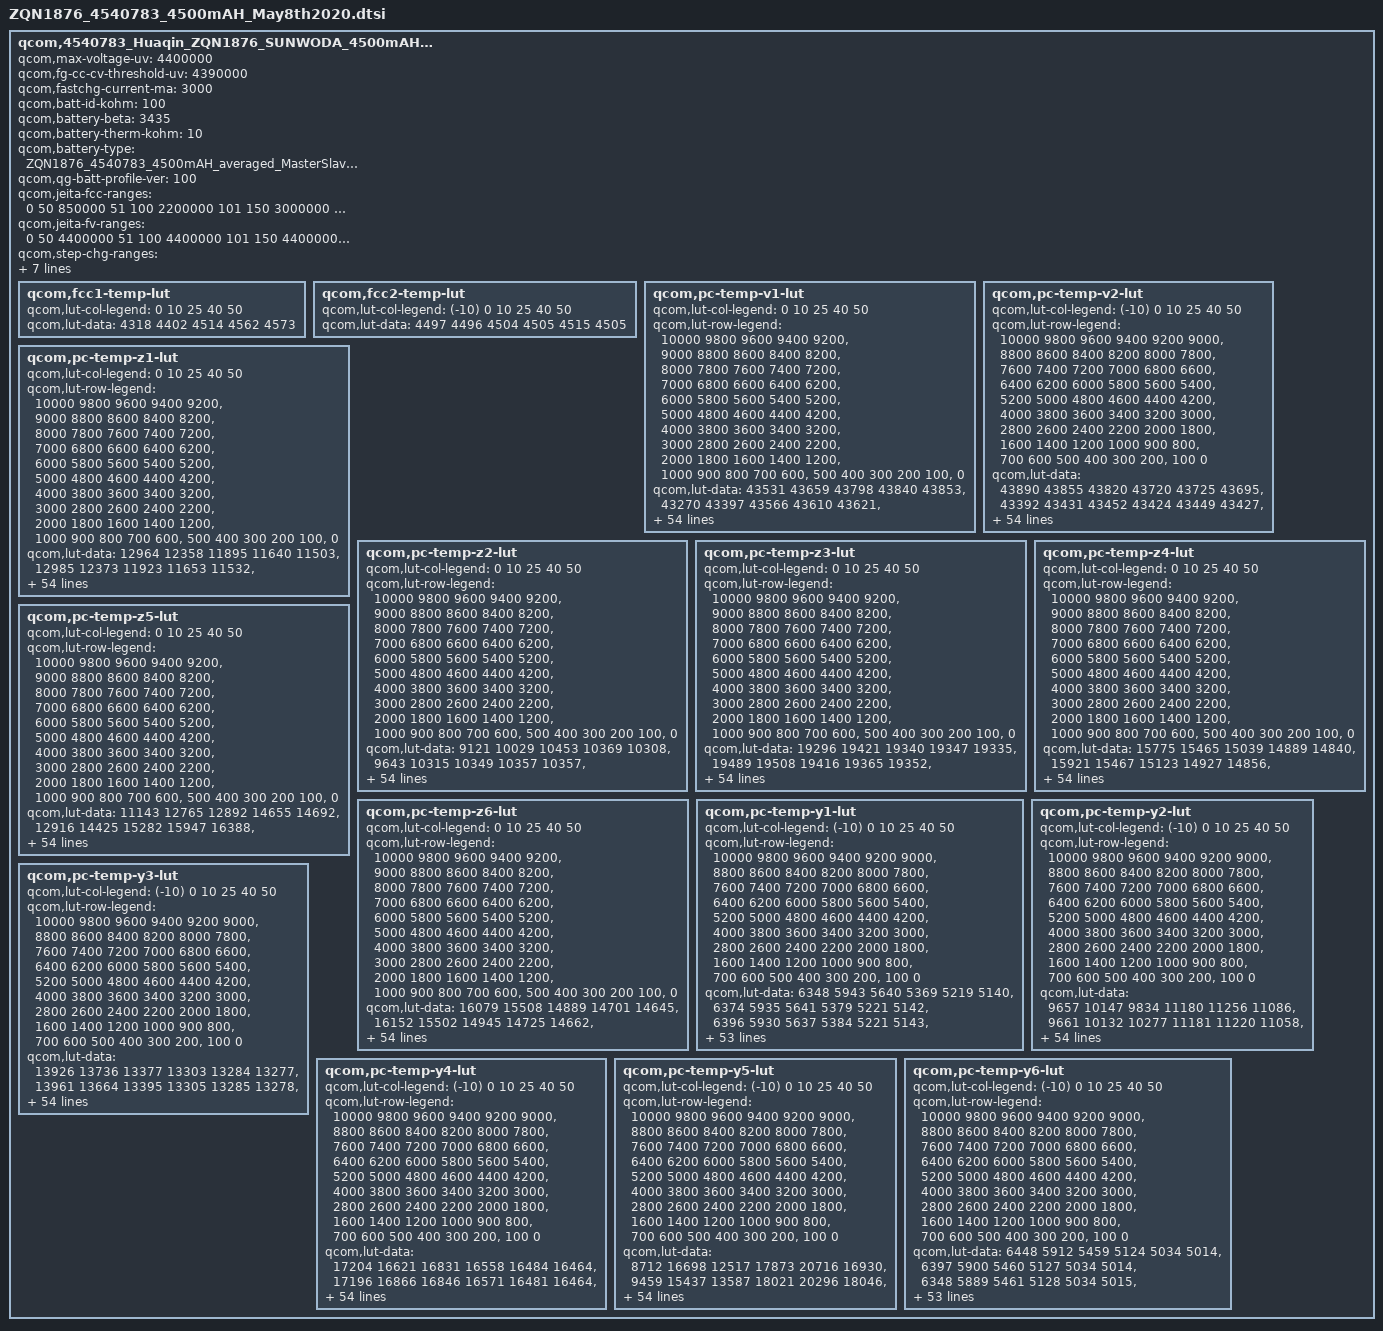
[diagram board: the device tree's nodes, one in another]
qcom,4540783_Huaqin_ZQN1876_SUNWODA_4500mAH_PM7250B {
    /* 4540783_Huaqin_ZQN1876_SUNWODA_4500mAH_PM7250B_averaged_MasterSlave_May8th2020 */
    qcom,max-voltage-uv = <4400000>;
    qcom,fg-cc-cv-threshold-uv = <4390000>;
    qcom,fastchg-current-ma = <3000>;
    qcom,batt-id-kohm = <100>;
    qcom,battery-beta = <3435>;
    qcom,battery-therm-kohm = <10>;
    qcom,battery-type = "ZQN1876_4540783_4500mAH_averaged_MasterSlave_May8th2020";
    qcom,qg-batt-profile-ver = <100>;

	qcom,jeita-fcc-ranges = <0  50  850000
				51 100  2200000
				101 150  3000000
				151 450  4400000
				451 600  2200000>;

	qcom,jeita-fv-ranges = <0   50  4400000
				51 100  4400000
				101 150  4400000
				151 450  4400000
				451 600  4100000>;

	qcom,step-chg-ranges = <3500000  4000000  4000000
				4000001  4200000  3500000
				4200001  4400000  2500000>;
	qcom,ocv-based-step-chg;

	/* COOL = 10 degc, WARM = 45 degC */
	qcom,jeita-soft-thresholds = <0x2AEE 0x0FB3>;
	/* COLD = 0 degC, HOT = 58 degC*/
	qcom,jeita-hard-thresholds = <0x3733 0x0ACB>;
	/* COOL hys = 13 degC, WARM hys = 42 degC */
	qcom,jeita-soft-hys-thresholds = <0x279A 0x1124>;
	qcom,jeita-soft-fcc-ua = <880000 2200000>;
	qcom,jeita-soft-fv-uv = <4400000 4100000>;
	qcom,fcc1-temp-lut {
		qcom,lut-col-legend = <0 10 25 40 50>;
		qcom,lut-data = <4318 4402 4514 4562 4573>;
	};

	qcom,fcc2-temp-lut {
		qcom,lut-col-legend = <(-10) 0 10 25 40 50>;
		qcom,lut-data = <4497 4496 4504 4505 4515 4505>;
	};

	qcom,pc-temp-v1-lut {
		qcom,lut-col-legend = <0 10 25 40 50>;
		qcom,lut-row-legend = <10000 9800 9600 9400 9200>,
			<9000 8800 8600 8400 8200>,
			<8000 7800 7600 7400 7200>,
			<7000 6800 6600 6400 6200>,
			<6000 5800 5600 5400 5200>,
			<5000 4800 4600 4400 4200>,
			<4000 3800 3600 3400 3200>,
			<3000 2800 2600 2400 2200>,
			<2000 1800 1600 1400 1200>,
			<1000 900 800 700 600>,
			<500 400 300 200 100>,
			<0>;
		qcom,lut-data = <43531 43659 43798 43840 43853>,
			<43270 43397 43566 43610 43621>,
			<43013 43146 43315 43373 43390>,
			<42767 42905 43068 43135 43159>,
			<42538 42671 42826 42899 42926>,
			<42320 42442 42586 42662 42689>,
			<42109 42218 42352 42428 42455>,
			<41906 42002 42121 42194 42223>,
			<41710 41793 41897 41963 41992>,
			<41524 41590 41677 41734 41762>,
			<41350 41404 41465 41507 41534>,
			<41160 41226 41271 41289 41311>,
			<40940 41027 41086 41077 41091>,
			<40699 40792 40873 40869 40879>,
			<40448 40548 40612 40649 40674>,
			<40165 40302 40360 40431 40477>,
			<39928 40053 40157 40238 40287>,
			<39791 39873 39980 40064 40105>,
			<39691 39769 39829 39900 39930>,
			<39587 39675 39713 39749 39770>,
			<39483 39528 39584 39598 39611>,
			<39371 39329 39376 39408 39421>,
			<39223 39133 39123 39172 39186>,
			<39032 38935 38938 38968 38976>,
			<38867 38758 38805 38814 38820>,
			<38747 38664 38695 38683 38688>,
			<38647 38608 38600 38570 38572>,
			<38572 38558 38519 38471 38471>,
			<38513 38502 38441 38382 38379>,
			<38466 38448 38367 38301 38293>,
			<38424 38398 38301 38229 38216>,
			<38389 38350 38247 38165 38147>,
			<38357 38306 38198 38109 38085>,
			<38329 38267 38155 38057 38027>,
			<38303 38232 38117 38012 37974>,
			<38274 38198 38078 37967 37923>,
			<38247 38169 38041 37920 37868>,
			<38210 38134 38001 37871 37811>,
			<38143 38073 37944 37808 37740>,
			<38048 37977 37857 37721 37648>,
			<37954 37869 37753 37618 37542>,
			<37858 37744 37633 37500 37424>,
			<37731 37600 37493 37363 37290>,
			<37549 37426 37330 37201 37126>,
			<37390 37288 37184 37067 36996>,
			<37284 37224 37087 36985 36920>,
			<37249 37187 37058 36958 36897>,
			<37217 37160 37042 36943 36880>,
			<37187 37136 37024 36924 36861>,
			<37127 37078 36975 36855 36785>,
			<36898 36826 36715 36566 36488>,
			<36443 36373 36276 36115 36043>,
			<35861 35786 35703 35527 35463>,
			<35073 34987 34915 34722 34669>,
			<33819 33729 33689 33451 33434>,
			<30000 30000 30000 30000 30000>;
	};

	qcom,pc-temp-v2-lut {
		qcom,lut-col-legend = <(-10) 0 10 25 40 50>;
		qcom,lut-row-legend = <10000 9800 9600 9400 9200 9000>,
			<8800 8600 8400 8200 8000 7800>,
			<7600 7400 7200 7000 6800 6600>,
			<6400 6200 6000 5800 5600 5400>,
			<5200 5000 4800 4600 4400 4200>,
			<4000 3800 3600 3400 3200 3000>,
			<2800 2600 2400 2200 2000 1800>,
			<1600 1400 1200 1000 900 800>,
			<700 600 500 400 300 200>,
			<100 0>;
		qcom,lut-data = <43890 43855 43820 43720 43725 43695>,
			<43392 43431 43452 43424 43449 43427>,
			<42957 43050 43119 43146 43184 43168>,
			<42599 42719 42827 42885 42930 42920>,
			<42300 42428 42571 42642 42688 42682>,
			<42023 42167 42326 42405 42450 42446>,
			<41694 41931 42082 42171 42214 42212>,
			<41416 41716 41841 41941 41981 41980>,
			<41371 41508 41576 41716 41752 41751>,
			<41376 41302 41271 41494 41529 41525>,
			<41379 41129 41066 41280 41307 41303>,
			<41200 41018 41000 41080 41088 41085>,
			<40820 40915 40951 40884 40872 40871>,
			<40433 40685 40776 40668 40664 40664>,
			<39972 40165 40278 40429 40463 40462>,
			<39603 39752 39890 40201 40268 40268>,
			<39402 39605 39765 39994 40079 40085>,
			<39243 39498 39675 39805 39898 39909>,
			<39049 39344 39540 39646 39730 39740>,
			<38815 39139 39355 39514 39579 39583>,
			<38626 38919 39158 39365 39410 39411>,
			<38506 38669 38949 39150 39187 39191>,
			<38413 38428 38735 38913 38954 38959>,
			<38335 38299 38542 38731 38770 38776>,
			<38270 38224 38357 38580 38615 38622>,
			<38212 38167 38216 38451 38483 38490>,
			<38157 38116 38122 38340 38370 38376>,
			<38105 38072 38051 38241 38271 38276>,
			<38053 38030 37995 38152 38181 38184>,
			<38002 37990 37951 38070 38099 38099>,
			<37952 37951 37913 37995 38026 38023>,
			<37903 37913 37881 37920 37960 37956>,
			<37854 37875 37850 37853 37899 37894>,
			<37801 37835 37817 37803 37833 37827>,
			<37745 37794 37781 37766 37763 37756>,
			<37687 37749 37741 37725 37689 37676>,
			<37627 37703 37696 37677 37609 37578>,
			<37565 37651 37643 37620 37527 37471>,
			<37493 37588 37578 37551 37448 37382>,
			<37411 37511 37497 37467 37370 37305>,
			<37324 37422 37401 37372 37287 37223>,
			<37231 37310 37281 37262 37191 37131>,
			<37141 37184 37151 37140 37080 37025>,
			<37064 37049 37024 36997 36935 36882>,
			<36991 36931 36912 36894 36830 36782>,
			<36915 36850 36818 36842 36795 36744>,
			<36868 36820 36778 36825 36782 36733>,
			<36814 36790 36734 36801 36765 36717>,
			<36744 36743 36679 36756 36727 36682>,
			<36618 36654 36584 36629 36608 36563>,
			<36371 36428 36371 36289 36262 36205>,
			<35964 35991 35923 35757 35741 35695>,
			<35379 35372 35283 35058 35070 35038>,
			<34530 34498 34390 34074 34142 34128>,
			<33145 33074 32953 32506 32726 32724>,
			<29068 28775 28334 28927 27750 28531>;
	};

	qcom,pc-temp-z1-lut {
		qcom,lut-col-legend = <0 10 25 40 50>;
		qcom,lut-row-legend = <10000 9800 9600 9400 9200>,
			<9000 8800 8600 8400 8200>,
			<8000 7800 7600 7400 7200>,
			<7000 6800 6600 6400 6200>,
			<6000 5800 5600 5400 5200>,
			<5000 4800 4600 4400 4200>,
			<4000 3800 3600 3400 3200>,
			<3000 2800 2600 2400 2200>,
			<2000 1800 1600 1400 1200>,
			<1000 900 800 700 600>,
			<500 400 300 200 100>,
			<0>;
		qcom,lut-data = <12964 12358 11895 11640 11503>,
			<12985 12373 11923 11653 11532>,
			<12984 12373 11922 11649 11529>,
			<12983 12367 11921 11646 11527>,
			<12980 12362 11913 11639 11523>,
			<12971 12356 11903 11629 11516>,
			<12961 12349 11894 11620 11510>,
			<12944 12344 11884 11612 11505>,
			<12929 12337 11877 11605 11502>,
			<12926 12332 11870 11602 11499>,
			<12927 12333 11866 11599 11497>,
			<12924 12336 11867 11598 11495>,
			<12895 12333 11869 11598 11494>,
			<12855 12302 11869 11598 11493>,
			<12836 12272 11855 11591 11492>,
			<12820 12270 11840 11579 11491>,
			<12809 12273 11837 11578 11491>,
			<12801 12275 11838 11580 11492>,
			<12789 12277 11840 11584 11493>,
			<12784 12281 11846 11588 11493>,
			<12777 12287 11852 11591 11494>,
			<12770 12300 11854 11593 11495>,
			<12778 12306 11855 11594 11496>,
			<12797 12304 11858 11596 11497>,
			<12808 12301 11868 11599 11500>,
			<12802 12302 11875 11602 11504>,
			<12792 12306 11873 11606 11508>,
			<12796 12308 11870 11610 11511>,
			<12817 12313 11870 11614 11515>,
			<12836 12322 11882 11618 11519>,
			<12840 12325 11892 11622 11523>,
			<12840 12324 11896 11625 11526>,
			<12840 12325 11898 11630 11530>,
			<12843 12330 11899 11633 11533>,
			<12845 12338 11898 11637 11538>,
			<12849 12344 11897 11641 11542>,
			<12866 12347 11897 11644 11546>,
			<12880 12347 11898 11647 11550>,
			<12888 12348 11902 11652 11554>,
			<12896 12350 11913 11661 11557>,
			<12897 12354 11923 11668 11561>,
			<12883 12376 11930 11671 11564>,
			<12885 12387 11937 11673 11568>,
			<12919 12369 11949 11678 11572>,
			<12941 12389 11953 11685 11576>,
			<12914 12380 11960 11688 11578>,
			<12917 12385 11947 11688 11579>,
			<12921 12377 11945 11690 11579>,
			<12903 12382 11954 11693 11583>,
			<12942 12400 11950 11698 11589>,
			<12928 12394 11962 11707 11596>,
			<12952 12423 11972 11722 11603>,
			<12962 12429 11990 11725 11611>,
			<12982 12474 12001 11742 11623>,
			<12982 12474 12001 11742 11623>,
			<12982 12474 12001 11742 11623>;
	};

	qcom,pc-temp-z2-lut {
		qcom,lut-col-legend = <0 10 25 40 50>;
		qcom,lut-row-legend = <10000 9800 9600 9400 9200>,
			<9000 8800 8600 8400 8200>,
			<8000 7800 7600 7400 7200>,
			<7000 6800 6600 6400 6200>,
			<6000 5800 5600 5400 5200>,
			<5000 4800 4600 4400 4200>,
			<4000 3800 3600 3400 3200>,
			<3000 2800 2600 2400 2200>,
			<2000 1800 1600 1400 1200>,
			<1000 900 800 700 600>,
			<500 400 300 200 100>,
			<0>;
		qcom,lut-data = <9121 10029 10453 10369 10308>,
			<9643 10315 10349 10357 10357>,
			<9954 10380 10513 10430 10343>,
			<10181 10389 10569 10499 10331>,
			<10181 10392 10548 10486 10323>,
			<10168 10379 10519 10445 10301>,
			<10156 10352 10496 10413 10274>,
			<10143 10333 10473 10383 10236>,
			<10132 10318 10455 10364 10206>,
			<10124 10309 10438 10362 10209>,
			<10119 10307 10429 10360 10223>,
			<10112 10306 10433 10363 10238>,
			<10099 10306 10446 10380 10258>,
			<10086 10321 10464 10400 10271>,
			<10084 10338 10500 10429 10259>,
			<10094 10348 10525 10462 10239>,
			<10108 10355 10499 10454 10237>,
			<10124 10363 10443 10377 10256>,
			<10144 10371 10429 10329 10281>,
			<10165 10381 10459 10337 10300>,
			<10187 10400 10502 10358 10323>,
			<10208 10430 10562 10417 10390>,
			<10224 10446 10630 10579 10580>,
			<10238 10446 10644 10669 10707>,
			<10251 10445 10617 10633 10708>,
			<10262 10446 10595 10581 10679>,
			<10271 10450 10615 10589 10627>,
			<10283 10456 10655 10642 10513>,
			<10298 10462 10663 10663 10424>,
			<10312 10470 10651 10569 10363>,
			<10323 10479 10634 10460 10312>,
			<10331 10491 10613 10442 10278>,
			<10341 10500 10592 10435 10250>,
			<10352 10503 10589 10435 10242>,
			<10363 10506 10609 10458 10265>,
			<10375 10509 10630 10492 10304>,
			<10388 10523 10643 10533 10357>,
			<10402 10541 10657 10591 10428>,
			<10425 10560 10672 10624 10474>,
			<10449 10583 10692 10647 10500>,
			<10397 10593 10705 10662 10519>,
			<10026 10594 10708 10668 10526>,
			<9908 10597 10709 10673 10523>,
			<10060 10622 10701 10671 10546>,
			<10054 10617 10716 10621 10541>,
			<10069 14375 10759 10549 10465>,
			<10196 13650 10724 10540 10464>,
			<10173 16147 10685 10568 10497>,
			<10128 21114 10688 10588 10542>,
			<10067 20543 10765 10677 10569>,
			<9888 19923 10753 10536 10401>,
			<9848 18828 10666 10450 10302>,
			<9718 18085 10651 10403 10271>,
			<9643 14449 10584 10365 10218>,
			<9643 14449 10584 10365 10218>,
			<9643 14449 10584 10365 10218>;
	};

	qcom,pc-temp-z3-lut {
		qcom,lut-col-legend = <0 10 25 40 50>;
		qcom,lut-row-legend = <10000 9800 9600 9400 9200>,
			<9000 8800 8600 8400 8200>,
			<8000 7800 7600 7400 7200>,
			<7000 6800 6600 6400 6200>,
			<6000 5800 5600 5400 5200>,
			<5000 4800 4600 4400 4200>,
			<4000 3800 3600 3400 3200>,
			<3000 2800 2600 2400 2200>,
			<2000 1800 1600 1400 1200>,
			<1000 900 800 700 600>,
			<500 400 300 200 100>,
			<0>;
		qcom,lut-data = <19296 19421 19340 19347 19335>,
			<19489 19508 19416 19365 19352>,
			<19629 19549 19445 19385 19363>,
			<19725 19572 19457 19396 19374>,
			<19737 19582 19463 19399 19379>,
			<19742 19585 19466 19401 19384>,
			<19744 19586 19466 19401 19385>,
			<19740 19586 19466 19402 19385>,
			<19734 19586 19465 19402 19384>,
			<19727 19585 19462 19400 19383>,
			<19718 19581 19459 19396 19381>,
			<19713 19572 19453 19394 19379>,
			<19716 19566 19445 19393 19377>,
			<19721 19560 19443 19392 19375>,
			<19728 19556 19446 19390 19371>,
			<19739 19554 19448 19389 19366>,
			<19747 19553 19445 19386 19362>,
			<19735 19550 19436 19380 19359>,
			<19704 19536 19429 19373 19356>,
			<19681 19522 19420 19366 19352>,
			<19666 19524 19415 19361 19349>,
			<19657 19535 19418 19361 19349>,
			<19661 19541 19424 19369 19357>,
			<19680 19540 19425 19373 19364>,
			<19691 19537 19417 19370 19366>,
			<19688 19534 19410 19367 19368>,
			<19681 19528 19415 19373 19373>,
			<19675 19525 19428 19397 19386>,
			<19671 19526 19437 19408 19393>,
			<19666 19528 19446 19406 19390>,
			<19660 19529 19451 19403 19384>,
			<19654 19529 19449 19399 19379>,
			<19647 19530 19443 19392 19373>,
			<19640 19528 19437 19386 19366>,
			<19633 19525 19432 19379 19360>,
			<19626 19521 19428 19374 19355>,
			<19619 19517 19424 19371 19352>,
			<19612 19513 19421 19368 19349>,
			<19608 19508 19418 19367 19348>,
			<19603 19503 19415 19366 19350>,
			<19562 19499 19412 19365 19352>,
			<19345 19494 19409 19365 19352>,
			<19263 19489 19407 19365 19353>,
			<19262 19483 19402 19365 19356>,
			<19262 19401 19390 19359 19354>,
			<19262 19258 19385 19345 19342>,
			<19261 19257 19383 19345 19333>,
			<19261 19257 19378 19338 19330>,
			<19261 19256 19375 19334 19323>,
			<19262 19256 19361 19332 19326>,
			<19263 19256 19374 19347 19343>,
			<19263 19256 19380 19354 19345>,
			<19265 19256 19359 19353 19346>,
			<19266 19257 19357 19351 19346>,
			<19266 19257 19357 19351 19346>,
			<19266 19257 19357 19351 19346>;
	};

	qcom,pc-temp-z4-lut {
		qcom,lut-col-legend = <0 10 25 40 50>;
		qcom,lut-row-legend = <10000 9800 9600 9400 9200>,
			<9000 8800 8600 8400 8200>,
			<8000 7800 7600 7400 7200>,
			<7000 6800 6600 6400 6200>,
			<6000 5800 5600 5400 5200>,
			<5000 4800 4600 4400 4200>,
			<4000 3800 3600 3400 3200>,
			<3000 2800 2600 2400 2200>,
			<2000 1800 1600 1400 1200>,
			<1000 900 800 700 600>,
			<500 400 300 200 100>,
			<0>;
		qcom,lut-data = <15775 15465 15039 14889 14840>,
			<15921 15467 15123 14927 14856>,
			<15754 15440 15081 14903 14843>,
			<15557 15289 15032 14869 14823>,
			<15417 15137 14968 14841 14804>,
			<15290 15050 14905 14812 14784>,
			<15188 14979 14863 14788 14766>,
			<15106 14923 14828 14767 14747>,
			<15039 14877 14800 14749 14732>,
			<14988 14841 14775 14734 14721>,
			<14947 14814 14756 14722 14713>,
			<14912 14792 14745 14717 14706>,
			<14875 14774 14736 14714 14702>,
			<14847 14755 14734 14712 14698>,
			<14843 14744 14737 14709 14694>,
			<14857 14751 14740 14706 14691>,
			<14869 14773 14735 14700 14687>,
			<14856 14781 14723 14689 14681>,
			<14820 14752 14712 14681 14676>,
			<14792 14719 14697 14680 14673>,
			<14771 14721 14689 14679 14670>,
			<14757 14747 14721 14690 14679>,
			<14762 14778 14790 14740 14727>,
			<14790 14827 14824 14776 14759>,
			<14812 14874 14840 14790 14761>,
			<14828 14878 14847 14797 14762>,
			<14842 14857 14834 14787 14756>,
			<14845 14835 14807 14748 14727>,
			<14835 14818 14786 14724 14706>,
			<14822 14802 14769 14715 14699>,
			<14811 14789 14757 14710 14695>,
			<14798 14778 14752 14707 14691>,
			<14786 14769 14749 14704 14688>,
			<14776 14763 14747 14703 14687>,
			<14766 14759 14745 14704 14687>,
			<14756 14755 14744 14704 14688>,
			<14746 14747 14742 14704 14689>,
			<14739 14742 14741 14705 14691>,
			<14734 14742 14741 14705 14693>,
			<14732 14742 14740 14708 14696>,
			<14763 14742 14740 14709 14697>,
			<14972 14732 14731 14703 14692>,
			<15049 14721 14718 14692 14685>,
			<15030 14711 14711 14690 14684>,
			<14950 14748 14692 14681 14677>,
			<14928 14859 14668 14666 14657>,
			<14920 14854 14662 14658 14655>,
			<14915 14848 14653 14647 14642>,
			<14908 14838 14644 14635 14629>,
			<14904 14835 14650 14635 14625>,
			<14909 14845 14656 14647 14643>,
			<14923 14852 14656 14645 14648>,
			<14930 14856 14677 14648 14651>,
			<14941 14858 14681 14652 14651>,
			<14941 14858 14681 14652 14651>,
			<14941 14858 14681 14652 14651>;
	};

	qcom,pc-temp-z5-lut {
		qcom,lut-col-legend = <0 10 25 40 50>;
		qcom,lut-row-legend = <10000 9800 9600 9400 9200>,
			<9000 8800 8600 8400 8200>,
			<8000 7800 7600 7400 7200>,
			<7000 6800 6600 6400 6200>,
			<6000 5800 5600 5400 5200>,
			<5000 4800 4600 4400 4200>,
			<4000 3800 3600 3400 3200>,
			<3000 2800 2600 2400 2200>,
			<2000 1800 1600 1400 1200>,
			<1000 900 800 700 600>,
			<500 400 300 200 100>,
			<0>;
		qcom,lut-data = <11143 12765 12892 14655 14692>,
			<12916 14425 15282 15947 16388>,
			<14412 15765 16546 17451 17462>,
			<15629 16889 17613 18504 18585>,
			<16354 17932 18509 18946 19382>,
			<16905 18919 19334 19219 20052>,
			<17452 19902 20211 19590 20671>,
			<18016 21090 21103 20175 21217>,
			<18549 22605 22075 20863 21787>,
			<19033 24066 23321 21650 22543>,
			<19517 25179 24262 22506 23422>,
			<20103 26208 24661 23144 24203>,
			<20883 27555 25076 23569 25056>,
			<21951 30404 26009 24132 25575>,
			<23732 32698 29518 25855 25470>,
			<27445 31915 32240 28009 25242>,
			<30098 29433 30610 28124 25260>,
			<29056 28377 27103 26436 25964>,
			<26502 28444 26513 25359 26762>,
			<25529 28603 30402 25880 27420>,
			<26033 32891 34254 26739 28057>,
			<27141 47305 35579 27233 28340>,
			<32432 54920 36428 27669 28580>,
			<47567 50806 35734 27617 28626>,
			<56265 43942 28779 23993 25438>,
			<54139 38978 23217 19604 20853>,
			<50220 34319 23484 20029 20702>,
			<47656 32029 24484 23539 23369>,
			<45862 32333 26159 26554 25721>,
			<44462 33113 30277 28503 27107>,
			<43469 34311 34128 30147 28241>,
			<42647 36953 36021 31614 29164>,
			<41866 39681 37414 32924 30000>,
			<41042 41687 38563 33545 30433>,
			<40295 43440 39682 33834 30648>,
			<39699 44230 40249 33985 30753>,
			<39186 44669 39944 33797 30536>,
			<39193 44926 39124 33168 29911>,
			<40539 44472 37864 32297 29264>,
			<42332 42954 35301 30213 28553>,
			<39619 41255 33082 28541 27945>,
			<19170 38971 32103 28374 27730>,
			<11492 37148 31236 28390 27896>,
			<11538 36192 29000 28352 30099>,
			<11749 28248 28974 27085 30111>,
			<11757 11875 31812 23821 25646>,
			<11693 11841 32831 24924 22064>,
			<11687 11808 31293 24228 23457>,
			<11681 11708 31832 26644 26009>,
			<11705 11736 24542 24946 28988>,
			<11733 11757 25148 24235 27268>,
			<11645 11651 24945 25322 24472>,
			<11578 11566 18078 23168 22382>,
			<11467 11473 17078 20573 20096>,
			<11467 11473 17078 20573 20096>,
			<11467 11473 17078 20573 20096>;
	};

	qcom,pc-temp-z6-lut {
		qcom,lut-col-legend = <0 10 25 40 50>;
		qcom,lut-row-legend = <10000 9800 9600 9400 9200>,
			<9000 8800 8600 8400 8200>,
			<8000 7800 7600 7400 7200>,
			<7000 6800 6600 6400 6200>,
			<6000 5800 5600 5400 5200>,
			<5000 4800 4600 4400 4200>,
			<4000 3800 3600 3400 3200>,
			<3000 2800 2600 2400 2200>,
			<2000 1800 1600 1400 1200>,
			<1000 900 800 700 600>,
			<500 400 300 200 100>,
			<0>;
		qcom,lut-data = <16079 15508 14889 14701 14645>,
			<16152 15502 14945 14725 14662>,
			<16063 15473 14934 14721 14661>,
			<15951 15382 14918 14714 14658>,
			<15851 15288 14887 14704 14653>,
			<15747 15226 14852 14689 14646>,
			<15661 15171 14827 14677 14638>,
			<15591 15128 14806 14667 14630>,
			<15532 15093 14787 14658 14622>,
			<15484 15062 14771 14649 14616>,
			<15443 15036 14758 14641 14611>,
			<15407 15012 14748 14637 14606>,
			<15367 14990 14740 14635 14603>,
			<15333 14964 14736 14634 14600>,
			<15320 14947 14735 14630 14596>,
			<15316 14948 14733 14626 14591>,
			<15311 14953 14728 14620 14587>,
			<15290 14955 14719 14613 14583>,
			<15252 14938 14711 14606 14579>,
			<15228 14919 14702 14602 14576>,
			<15215 14922 14697 14599 14572>,
			<15208 14941 14714 14605 14576>,
			<15214 14962 14749 14631 14601>,
			<15238 14984 14763 14649 14619>,
			<15256 15004 14767 14654 14623>,
			<15261 15005 14769 14657 14626>,
			<15265 14995 14767 14656 14625>,
			<15265 14985 14763 14653 14621>,
			<15261 14981 14761 14649 14616>,
			<15256 14977 14760 14646 14612>,
			<15250 14974 14759 14643 14608>,
			<15242 14970 14756 14639 14604>,
			<15235 14967 14753 14636 14600>,
			<15231 14966 14751 14633 14597>,
			<15227 14965 14749 14630 14594>,
			<15223 14964 14747 14628 14591>,
			<15219 14963 14747 14627 14591>,
			<15217 14962 14746 14626 14591>,
			<15220 14963 14746 14626 14591>,
			<15224 14966 14747 14628 14593>,
			<15224 14967 14748 14629 14596>,
			<15217 14966 14745 14627 14594>,
			<15215 14966 14742 14624 14592>,
			<15218 14967 14739 14624 14594>,
			<15204 14953 14730 14619 14590>,
			<15197 14936 14720 14605 14576>,
			<15194 14936 14718 14602 14571>,
			<15194 14933 14712 14594 14564>,
			<15194 14929 14708 14587 14554>,
			<15198 14932 14707 14587 14555>,
			<15211 14946 14720 14603 14573>,
			<15222 14956 14727 14608 14579>,
			<15239 14966 14731 14612 14583>,
			<15267 14981 14738 14616 14586>,
			<15267 14981 14738 14616 14586>,
			<15267 14981 14738 14616 14586>;
	};

	qcom,pc-temp-y1-lut {
		qcom,lut-col-legend = <(-10) 0 10 25 40 50>;
		qcom,lut-row-legend = <10000 9800 9600 9400 9200 9000>,
			<8800 8600 8400 8200 8000 7800>,
			<7600 7400 7200 7000 6800 6600>,
			<6400 6200 6000 5800 5600 5400>,
			<5200 5000 4800 4600 4400 4200>,
			<4000 3800 3600 3400 3200 3000>,
			<2800 2600 2400 2200 2000 1800>,
			<1600 1400 1200 1000 900 800>,
			<700 600 500 400 300 200>,
			<100 0>;
		qcom,lut-data = <6348 5943 5640 5369 5219 5140>,
			<6374 5935 5641 5379 5221 5142>,
			<6396 5930 5637 5384 5221 5143>,
			<6414 5927 5630 5387 5220 5144>,
			<6425 5926 5624 5387 5219 5144>,
			<6429 5927 5622 5385 5216 5144>,
			<6424 5933 5620 5380 5212 5142>,
			<6415 5943 5618 5372 5206 5138>,
			<6415 5945 5619 5369 5203 5135>,
			<6425 5943 5622 5367 5202 5132>,
			<6431 5941 5625 5365 5200 5130>,
			<6424 5944 5631 5364 5197 5129>,
			<6414 5948 5637 5363 5195 5128>,
			<6414 5948 5636 5362 5192 5126>,
			<6429 5942 5626 5361 5189 5125>,
			<6441 5938 5621 5360 5188 5125>,
			<6441 5933 5622 5364 5190 5126>,
			<6438 5925 5625 5368 5193 5127>,
			<6436 5928 5628 5368 5193 5127>,
			<6429 5943 5630 5363 5191 5127>,
			<6425 5953 5633 5359 5190 5127>,
			<6421 5951 5636 5359 5192 5128>,
			<6415 5946 5640 5360 5194 5129>,
			<6414 5943 5643 5362 5196 5131>,
			<6410 5940 5648 5367 5196 5132>,
			<6405 5938 5651 5371 5197 5134>,
			<6406 5937 5647 5373 5199 5136>,
			<6411 5937 5642 5376 5202 5139>,
			<6413 5938 5641 5378 5205 5141>,
			<6417 5944 5640 5379 5210 5144>,
			<6420 5951 5639 5380 5214 5147>,
			<6410 5954 5640 5384 5218 5150>,
			<6396 5956 5641 5388 5223 5153>,
			<6395 5953 5644 5391 5226 5156>,
			<6411 5937 5653 5394 5230 5160>,
			<6422 5927 5657 5396 5232 5162>,
			<6421 5933 5652 5399 5234 5164>,
			<6418 5945 5646 5402 5235 5165>,
			<6412 5953 5645 5401 5237 5167>,
			<6399 5959 5641 5396 5239 5168>,
			<6392 5963 5638 5394 5242 5170>,
			<6405 5967 5642 5406 5243 5172>,
			<6419 5968 5646 5417 5246 5175>,
			<6424 5941 5647 5423 5254 5179>,
			<6419 5931 5655 5424 5259 5183>,
			<6436 5966 5678 5426 5263 5184>,
			<6464 5969 5672 5429 5262 5185>,
			<6484 5964 5676 5437 5263 5184>,
			<6491 5977 5671 5422 5260 5183>,
			<6454 5991 5673 5420 5259 5183>,
			<6487 5998 5671 5422 5262 5187>,
			<6515 6002 5686 5442 5272 5193>,
			<6510 6032 5706 5467 5282 5199>,
			<6537 6069 5735 5458 5294 5209>,
			<6537 6069 5735 5458 5294 5209>,
			<6537 6069 5735 5458 5294 5209>;
	};

	qcom,pc-temp-y2-lut {
		qcom,lut-col-legend = <(-10) 0 10 25 40 50>;
		qcom,lut-row-legend = <10000 9800 9600 9400 9200 9000>,
			<8800 8600 8400 8200 8000 7800>,
			<7600 7400 7200 7000 6800 6600>,
			<6400 6200 6000 5800 5600 5400>,
			<5200 5000 4800 4600 4400 4200>,
			<4000 3800 3600 3400 3200 3000>,
			<2800 2600 2400 2200 2000 1800>,
			<1600 1400 1200 1000 900 800>,
			<700 600 500 400 300 200>,
			<100 0>;
		qcom,lut-data = <9657 10147 9834 11180 11256 11086>,
			<9661 10132 10277 11181 11220 11058>,
			<9664 10124 10552 11168 11177 11019>,
			<9667 10124 10701 11148 11134 10976>,
			<9668 10131 10761 11128 11097 10939>,
			<9669 10142 10772 11113 11071 10917>,
			<9668 10321 10653 11098 11029 10906>,
			<9666 10587 10470 11080 10979 10896>,
			<9666 10571 10497 11068 10961 10884>,
			<9668 10206 10810 11053 10958 10864>,
			<9669 9968 11008 11033 10958 10853>,
			<9669 10175 10907 10995 10944 10855>,
			<9669 10498 10753 10954 10926 10860>,
			<9669 10475 10747 10969 10936 10857>,
			<9668 10008 10875 11081 10977 10844>,
			<9666 9699 11018 11188 11018 10837>,
			<9666 9696 11153 11248 11053 10871>,
			<9666 9695 11273 11303 11097 10933>,
			<9666 9693 11324 11371 11175 10996>,
			<9666 9687 11352 11466 11315 11119>,
			<9666 9683 11362 11513 11384 11198>,
			<9665 9681 11326 11474 11371 11185>,
			<9665 9679 11253 11416 11344 11154>,
			<9665 9678 11188 11401 11305 11151>,
			<9665 9676 11123 11398 11234 11155>,
			<9665 9674 11021 11397 11198 11156>,
			<9664 9672 10608 11417 11214 11166>,
			<9664 9670 10097 11452 11244 11187>,
			<9664 9669 9985 11477 11278 11211>,
			<9664 9668 9968 11509 11332 11257>,
			<9663 9667 9952 11526 11391 11296>,
			<9663 9666 9876 11508 11476 11321>,
			<9663 9665 9768 11474 11549 11340>,
			<9663 9664 9725 11441 11546 11352>,
			<9663 9663 9705 11405 11497 11356>,
			<9663 9663 9694 11366 11455 11352>,
			<9662 9662 9687 11328 11422 11331>,
			<9662 9662 9681 11285 11393 11304>,
			<9662 9662 9677 11228 11370 11290>,
			<9662 9661 9673 11148 11329 11280>,
			<9662 9661 9669 11082 11307 11264>,
			<9662 9661 9667 11044 11331 11210>,
			<9661 9660 9665 10999 11339 11159>,
			<9661 9660 9663 10893 11179 11146>,
			<9661 9660 9662 10817 11035 11039>,
			<9660 9659 9663 10830 11022 10959>,
			<9660 9659 9662 10824 11088 10935>,
			<9660 9659 9662 10797 11094 11007>,
			<9660 9659 9661 10806 11120 11022>,
			<9659 9658 9661 10814 11107 11003>,
			<9658 9658 9661 10710 11038 10904>,
			<9658 9658 9660 10613 10949 10848>,
			<9657 9657 9658 10529 10869 10751>,
			<9654 9657 9657 10461 10835 10700>,
			<9654 9657 9657 10461 10835 10700>,
			<9654 9657 9657 10461 10835 10700>;
	};

	qcom,pc-temp-y3-lut {
		qcom,lut-col-legend = <(-10) 0 10 25 40 50>;
		qcom,lut-row-legend = <10000 9800 9600 9400 9200 9000>,
			<8800 8600 8400 8200 8000 7800>,
			<7600 7400 7200 7000 6800 6600>,
			<6400 6200 6000 5800 5600 5400>,
			<5200 5000 4800 4600 4400 4200>,
			<4000 3800 3600 3400 3200 3000>,
			<2800 2600 2400 2200 2000 1800>,
			<1600 1400 1200 1000 900 800>,
			<700 600 500 400 300 200>,
			<100 0>;
		qcom,lut-data = <13926 13736 13377 13303 13284 13277>,
			<13961 13664 13395 13305 13285 13278>,
			<13962 13617 13407 13307 13285 13279>,
			<13937 13590 13414 13308 13286 13280>,
			<13892 13577 13417 13310 13286 13281>,
			<13835 13574 13417 13311 13286 13282>,
			<13734 13593 13413 13312 13286 13282>,
			<13628 13622 13406 13313 13285 13282>,
			<13609 13606 13402 13313 13286 13282>,
			<13611 13489 13399 13314 13288 13283>,
			<13614 13412 13395 13315 13289 13284>,
			<13632 13423 13380 13317 13289 13284>,
			<13656 13440 13360 13319 13289 13285>,
			<13652 13442 13357 13319 13289 13285>,
			<13603 13436 13358 13318 13291 13285>,
			<13570 13431 13359 13316 13293 13285>,
			<13582 13435 13359 13314 13294 13287>,
			<13601 13441 13359 13311 13295 13289>,
			<13602 13442 13356 13309 13295 13289>,
			<13591 13439 13350 13308 13295 13290>,
			<13583 13435 13343 13307 13294 13290>,
			<13589 13414 13334 13303 13290 13287>,
			<13602 13386 13324 13299 13286 13282>,
			<13616 13382 13320 13296 13283 13280>,
			<13634 13393 13319 13295 13281 13278>,
			<13654 13407 13317 13294 13281 13278>,
			<13676 13427 13296 13294 13280 13278>,
			<13701 13452 13269 13293 13280 13278>,
			<13726 13477 13270 13293 13280 13278>,
			<13751 13501 13296 13292 13280 13277>,
			<13778 13528 13316 13292 13280 13276>,
			<13807 13560 13323 13291 13280 13276>,
			<13838 13595 13329 13290 13280 13277>,
			<13868 13630 13336 13290 13280 13277>,
			<13898 13665 13346 13291 13280 13277>,
			<13928 13701 13359 13292 13280 13278>,
			<13958 13735 13374 13294 13279 13277>,
			<13989 13769 13393 13295 13279 13277>,
			<14020 13803 13416 13296 13279 13277>,
			<14052 13838 13446 13297 13280 13277>,
			<14084 13871 13481 13298 13281 13278>,
			<14115 13901 13523 13301 13283 13280>,
			<14149 13930 13570 13305 13285 13281>,
			<14194 13962 13621 13306 13282 13279>,
			<14249 13999 13677 13309 13283 13280>,
			<14251 13985 13641 13309 13287 13283>,
			<14292 14015 13679 13315 13291 13286>,
			<14335 14060 13723 13320 13294 13288>,
			<14399 14103 13761 13326 13296 13289>,
			<14466 14140 13785 13329 13295 13288>,
			<14534 14188 13808 13327 13292 13284>,
			<14618 14242 13849 13331 13293 13285>,
			<14765 14341 13979 13341 13299 13291>,
			<15402 14457 14128 13361 13306 13297>,
			<15402 14457 14128 13361 13306 13297>,
			<15402 14457 14128 13361 13306 13297>;
	};

	qcom,pc-temp-y4-lut {
		qcom,lut-col-legend = <(-10) 0 10 25 40 50>;
		qcom,lut-row-legend = <10000 9800 9600 9400 9200 9000>,
			<8800 8600 8400 8200 8000 7800>,
			<7600 7400 7200 7000 6800 6600>,
			<6400 6200 6000 5800 5600 5400>,
			<5200 5000 4800 4600 4400 4200>,
			<4000 3800 3600 3400 3200 3000>,
			<2800 2600 2400 2200 2000 1800>,
			<1600 1400 1200 1000 900 800>,
			<700 600 500 400 300 200>,
			<100 0>;
		qcom,lut-data = <17204 16621 16831 16558 16484 16464>,
			<17196 16866 16846 16571 16481 16464>,
			<17192 17023 16876 16578 16478 16463>,
			<17192 17111 16911 16583 16476 16461>,
			<17196 17149 16940 16585 16474 16460>,
			<17203 17157 16953 16585 16474 16459>,
			<17271 17093 16954 16581 16474 16459>,
			<17404 16992 16954 16576 16475 16460>,
			<17545 17029 16949 16574 16476 16460>,
			<17723 17331 16923 16574 16476 16461>,
			<17816 17529 16906 16574 16476 16462>,
			<17695 17521 17062 16573 16479 16463>,
			<17453 17498 17299 16572 16483 16465>,
			<17248 17416 17281 16575 16487 16468>,
			<17047 17131 16972 16588 16494 16474>,
			<16915 16951 16779 16602 16501 16480>,
			<16867 16963 16831 16612 16510 16484>,
			<16835 16982 16910 16621 16521 16489>,
			<16790 16974 16919 16636 16537 16500>,
			<16730 16898 16890 16664 16560 16524>,
			<16697 16807 16850 16679 16571 16536>,
			<16695 16712 16791 16636 16547 16521>,
			<16694 16626 16716 16565 16509 16493>,
			<16694 16612 16641 16531 16488 16477>,
			<16698 16621 16557 16511 16472 16464>,
			<16701 16626 16516 16502 16466 16459>,
			<16701 16624 16549 16500 16466 16459>,
			<16702 16619 16595 16499 16468 16459>,
			<16703 16619 16599 16499 16470 16460>,
			<16709 16628 16576 16499 16476 16466>,
			<16716 16638 16561 16499 16482 16474>,
			<16721 16646 16575 16493 16491 16483>,
			<16726 16655 16600 16484 16499 16492>,
			<16732 16665 16620 16485 16498 16494>,
			<16740 16676 16640 16493 16492 16493>,
			<16747 16687 16657 16501 16485 16492>,
			<16751 16699 16673 16506 16473 16477>,
			<16754 16708 16687 16510 16462 16457>,
			<16753 16711 16692 16515 16462 16455>,
			<16743 16712 16696 16520 16465 16459>,
			<16737 16712 16697 16526 16470 16465>,
			<16739 16705 16694 16535 16477 16472>,
			<16744 16691 16691 16545 16480 16476>,
			<16757 16672 16696 16554 16474 16459>,
			<16780 16666 16700 16565 16475 16455>,
			<16763 16658 16691 16552 16478 16467>,
			<16780 16671 16708 16569 16493 16489>,
			<16801 16692 16739 16593 16518 16519>,
			<16825 16721 16785 16627 16549 16547>,
			<16841 16774 16839 16639 16550 16543>,
			<16836 16768 16863 16612 16502 16478>,
			<16824 16746 16827 16612 16497 16475>,
			<16835 16749 16818 16640 16515 16482>,
			<17081 16775 16828 16697 16549 16502>,
			<17081 16775 16828 16697 16549 16502>,
			<17081 16775 16828 16697 16549 16502>;
	};

	qcom,pc-temp-y5-lut {
		qcom,lut-col-legend = <(-10) 0 10 25 40 50>;
		qcom,lut-row-legend = <10000 9800 9600 9400 9200 9000>,
			<8800 8600 8400 8200 8000 7800>,
			<7600 7400 7200 7000 6800 6600>,
			<6400 6200 6000 5800 5600 5400>,
			<5200 5000 4800 4600 4400 4200>,
			<4000 3800 3600 3400 3200 3000>,
			<2800 2600 2400 2200 2000 1800>,
			<1600 1400 1200 1000 900 800>,
			<700 600 500 400 300 200>,
			<100 0>;
		qcom,lut-data = <8712 16698 12517 17873 20716 16930>,
			<9459 15437 13587 18021 20296 18046>,
			<12417 14865 14919 18251 19840 18821>,
			<14147 14859 16228 18497 19401 19310>,
			<14957 15295 17224 18692 19030 19563>,
			<15157 16055 17618 18772 18779 19634>,
			<13985 19395 17521 18763 18111 19361>,
			<12157 23863 17265 18737 17208 18859>,
			<12225 23565 16531 18680 17053 18520>,
			<14918 17427 14302 18499 17483 18237>,
			<18326 13405 12955 18208 17666 17964>,
			<22650 17029 14457 17233 17103 17677>,
			<26809 22729 16734 16026 16341 17336>,
			<26181 22893 17033 15961 16070 16830>,
			<18921 17747 16449 16677 16229 16031>,
			<14153 14359 16090 17114 16295 15612>,
			<15790 15897 16884 16570 16022 15785>,
			<18382 18828 18465 15773 15729 16073>,
			<18398 20885 19979 15917 15754 16199>,
			<15653 22638 21714 17512 16140 16244>,
			<13509 23465 22897 19357 16742 16406>,
			<12981 20170 23322 21281 18631 17654>,
			<12666 14750 23642 23045 20734 19363>,
			<12568 13114 24352 23597 20964 19961>,
			<12522 12653 25771 23654 20682 20232>,
			<12504 12481 26560 23589 20387 20331>,
			<12630 12716 21315 23535 19687 20171>,
			<12866 13131 13592 23501 18892 19796>,
			<13017 13319 12412 23683 18706 19098>,
			<13109 13393 13350 24372 18724 17641>,
			<13226 13487 13989 24769 18850 16857>,
			<13498 13724 14066 24201 19288 17014>,
			<13822 14046 14111 23260 19958 17398>,
			<13950 14282 14154 22664 20684 18262>,
			<13995 14456 14210 22205 21555 20303>,
			<14050 14643 14282 21677 21907 21625>,
			<14247 14946 14407 20990 21343 21934>,
			<14493 15248 14568 20190 20478 22020>,
			<14536 15325 14713 19245 19885 21719>,
			<14499 15341 14872 18015 19355 20793>,
			<14430 15343 14933 17290 19170 20251>,
			<13888 15128 14736 17193 19802 21136>,
			<13289 14835 14595 17095 20169 21945>,
			<13185 14687 14498 16391 18172 20434>,
			<13211 14364 14553 16376 17152 19206>,
			<13614 13943 14378 16785 18093 17972>,
			<13589 13951 14519 16998 18258 17746>,
			<13682 14054 14819 16919 18186 17193>,
			<14075 14218 15594 17202 17702 16723>,
			<14373 14231 16361 17805 17755 16579>,
			<14283 14729 16703 18014 18640 18141>,
			<14114 14504 15694 17888 19297 17385>,
			<14115 14422 14617 17614 19831 19991>,
			<12495 14384 13923 18498 22079 23444>,
			<12495 14384 13923 18498 22079 23444>,
			<12495 14384 13923 18498 22079 23444>;
	};

	qcom,pc-temp-y6-lut {
		qcom,lut-col-legend = <(-10) 0 10 25 40 50>;
		qcom,lut-row-legend = <10000 9800 9600 9400 9200 9000>,
			<8800 8600 8400 8200 8000 7800>,
			<7600 7400 7200 7000 6800 6600>,
			<6400 6200 6000 5800 5600 5400>,
			<5200 5000 4800 4600 4400 4200>,
			<4000 3800 3600 3400 3200 3000>,
			<2800 2600 2400 2200 2000 1800>,
			<1600 1400 1200 1000 900 800>,
			<700 600 500 400 300 200>,
			<100 0>;
		qcom,lut-data = <6448 5912 5459 5124 5034 5014>,
			<6397 5900 5460 5127 5034 5014>,
			<6348 5889 5461 5128 5034 5015>,
			<6301 5877 5461 5128 5033 5015>,
			<6259 5866 5461 5127 5032 5015>,
			<6220 5856 5460 5126 5032 5015>,
			<6179 5845 5454 5123 5031 5016>,
			<6146 5835 5442 5120 5031 5016>,
			<6149 5827 5429 5118 5031 5016>,
			<6195 5820 5413 5117 5032 5016>,
			<6226 5817 5404 5116 5033 5017>,
			<6202 5829 5438 5116 5033 5017>,
			<6149 5848 5489 5116 5034 5018>,
			<6087 5833 5481 5116 5035 5019>,
			<5997 5733 5398 5118 5038 5021>,
			<5946 5667 5346 5119 5041 5022>,
			<5944 5676 5361 5120 5045 5025>,
			<5942 5691 5384 5122 5049 5027>,
			<5935 5691 5387 5124 5054 5032>,
			<5913 5675 5377 5131 5059 5038>,
			<5899 5654 5364 5135 5062 5042>,
			<5904 5624 5345 5120 5052 5035>,
			<5915 5594 5323 5097 5038 5023>,
			<5927 5591 5304 5086 5030 5017>,
			<5942 5609 5286 5080 5024 5012>,
			<5959 5631 5278 5077 5022 5010>,
			<5976 5651 5282 5077 5022 5011>,
			<5995 5673 5290 5078 5022 5011>,
			<6014 5697 5301 5079 5023 5012>,
			<6035 5723 5318 5080 5025 5013>,
			<6057 5751 5339 5081 5028 5015>,
			<6081 5781 5363 5080 5031 5018>,
			<6106 5813 5391 5079 5034 5021>,
			<6132 5845 5419 5080 5034 5022>,
			<6158 5879 5450 5085 5033 5022>,
			<6185 5912 5482 5091 5031 5022>,
			<6210 5943 5515 5095 5028 5018>,
			<6235 5974 5551 5100 5025 5012>,
			<6259 6004 5589 5105 5025 5012>,
			<6283 6034 5629 5111 5027 5014>,
			<6308 6061 5670 5118 5030 5016>,
			<6334 6084 5714 5128 5034 5020>,
			<6364 6105 5759 5141 5036 5022>,
			<6406 6126 5809 5154 5034 5016>,
			<6462 6155 5862 5172 5037 5016>,
			<6465 6145 5830 5162 5042 5023>,
			<6507 6172 5869 5177 5048 5031>,
			<6550 6216 5914 5192 5058 5042>,
			<6609 6260 5959 5211 5068 5050>,
			<6668 6306 5994 5219 5067 5048>,
			<6729 6347 6022 5215 5052 5027>,
			<6804 6390 6052 5236 5053 5027>,
			<6940 6476 6163 5278 5065 5035>,
			<7576 6586 6294 5339 5083 5047>,
			<7576 6586 6294 5339 5083 5047>,
			<7576 6586 6294 5339 5083 5047>;
	};

};
